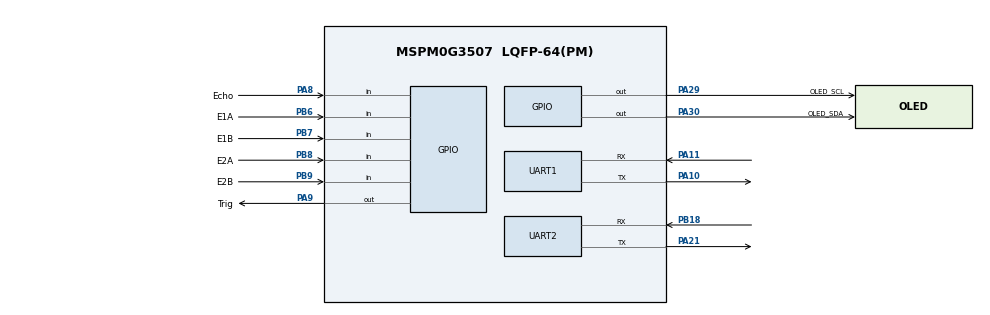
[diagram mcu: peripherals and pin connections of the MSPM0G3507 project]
/**
 * These arguments were used when this file was generated. They will be automatically applied on subsequent loads
 * via the GUI or CLI. Run CLI with '--help' for additional information on how to override these arguments.
 * @cliArgs --device "MSPM0G350X" --part "Default" --package "LQFP-64(PM)" --product "mspm0_sdk@2.10.00.04"
 * @v2CliArgs --device "MSPM0G3507" --package "LQFP-64(PM)" --product "mspm0_sdk@2.10.00.04"
 * @versions {"tool":"1.27.0+4565"}
 */

/**
 * Import the modules used in this configuration.
 */
const GPIO   = scripting.addModule("/ti/driverlib/GPIO", {}, false);
const GPIO1  = GPIO.addInstance();
const GPIO2  = GPIO.addInstance();
const GPIO3  = GPIO.addInstance();
const SYSCTL = scripting.addModule("/ti/driverlib/SYSCTL");
const TIMER  = scripting.addModule("/ti/driverlib/TIMER", {}, false);
const TIMER1 = TIMER.addInstance();
const TIMER2 = TIMER.addInstance();
const UART   = scripting.addModule("/ti/driverlib/UART", {}, false);
const UART1  = UART.addInstance();
const UART2  = UART.addInstance();

/**
 * Write custom configuration values to the imported modules.
 */
GPIO1.port                                = "PORTB";
GPIO1.$name                               = "ENCODER";
GPIO1.associatedPins.create(4);
GPIO1.associatedPins[0].$name             = "E1A";
GPIO1.associatedPins[0].direction         = "INPUT";
GPIO1.associatedPins[0].interruptEn       = true;
GPIO1.associatedPins[0].polarity          = "RISE";
GPIO1.associatedPins[0].assignedPin       = "6";
GPIO1.associatedPins[0].internalResistor  = "PULL_DOWN";
GPIO1.associatedPins[0].interruptPriority = "0";
GPIO1.associatedPins[0].pin.$assign       = "PB6";
GPIO1.associatedPins[1].$name             = "E1B";
GPIO1.associatedPins[1].direction         = "INPUT";
GPIO1.associatedPins[1].assignedPin       = "7";
GPIO1.associatedPins[1].interruptEn       = true;
GPIO1.associatedPins[1].polarity          = "RISE";
GPIO1.associatedPins[1].internalResistor  = "PULL_DOWN";
GPIO1.associatedPins[1].interruptPriority = "0";
GPIO1.associatedPins[1].pin.$assign       = "PB7";
GPIO1.associatedPins[2].$name             = "E2A";
GPIO1.associatedPins[2].direction         = "INPUT";
GPIO1.associatedPins[2].interruptEn       = true;
GPIO1.associatedPins[2].polarity          = "RISE";
GPIO1.associatedPins[2].assignedPin       = "8";
GPIO1.associatedPins[2].internalResistor  = "PULL_DOWN";
GPIO1.associatedPins[2].interruptPriority = "0";
GPIO1.associatedPins[2].pin.$assign       = "PB8";
GPIO1.associatedPins[3].$name             = "E2B";
GPIO1.associatedPins[3].direction         = "INPUT";
GPIO1.associatedPins[3].interruptEn       = true;
GPIO1.associatedPins[3].polarity          = "RISE";
GPIO1.associatedPins[3].assignedPin       = "9";
GPIO1.associatedPins[3].internalResistor  = "PULL_DOWN";
GPIO1.associatedPins[3].interruptPriority = "0";
GPIO1.associatedPins[3].pin.$assign       = "PB9";

const Board = scripting.addModule("/ti/driverlib/Board", {}, false);

GPIO2.port                                = "PORTA";
GPIO2.$name                               = "SR04";
GPIO2.associatedPins.create(2);
GPIO2.associatedPins[0].assignedPin       = "9";
GPIO2.associatedPins[0].$name             = "Trig";
GPIO2.associatedPins[0].initialValue      = "SET";
GPIO2.associatedPins[0].pin.$assign       = "PA9";
GPIO2.associatedPins[1].direction         = "INPUT";
GPIO2.associatedPins[1].assignedPin       = "8";
GPIO2.associatedPins[1].interruptEn       = true;
GPIO2.associatedPins[1].polarity          = "RISE_FALL";
GPIO2.associatedPins[1].$name             = "Echo";
GPIO2.associatedPins[1].interruptPriority = "1";
GPIO2.associatedPins[1].pin.$assign       = "PA8";

GPIO3.$name                         = "OLED";
GPIO3.port                          = "PORTA";
GPIO3.associatedPins.create(2);
GPIO3.associatedPins[0].$name       = "OLED_SCL";
GPIO3.associatedPins[0].assignedPin = "29";
GPIO3.associatedPins[0].pin.$assign = "PA29";
GPIO3.associatedPins[1].$name       = "OLED_SDA";
GPIO3.associatedPins[1].assignedPin = "30";
GPIO3.associatedPins[1].pin.$assign = "PA30";

SYSCTL.forceDefaultClkConfig = true;

TIMER1.timerMode          = "PERIODIC";
TIMER1.interrupts         = ["ZERO"];
TIMER1.timerStartTimer    = true;
TIMER1.$name              = "TIMER_ENCODER";
TIMER1.timerClkDiv        = 8;
TIMER1.timerClkPrescale   = 10;
TIMER1.interruptPriority  = "0";
TIMER1.timerPeriod        = "10 ms";
TIMER1.peripheral.$assign = "TIMA0";

TIMER2.timerPeriod        = "1 ms";
TIMER2.timerStartTimer    = true;
TIMER2.timerMode          = "PERIODIC_UP";
TIMER2.interrupts         = ["LOAD"];
TIMER2.$name              = "TIMER_SR04";
TIMER2.timerClkPrescale   = 40;
TIMER2.interruptPriority  = "1";
TIMER2.peripheral.$assign = "TIMA1";

UART1.$name                    = "UART_0";
UART1.peripheral.$assign       = "UART0";
UART1.peripheral.rxPin.$assign = "PA11";
UART1.peripheral.txPin.$assign = "PA10";
UART1.txPinConfig.$name        = "ti_driverlib_gpio_GPIOPinGeneric0";
UART1.rxPinConfig.$name        = "ti_driverlib_gpio_GPIOPinGeneric1";

UART2.$name                            = "Bluetooth";
UART2.targetBaudRate                   = 115200;
UART2.enabledInterrupts                = ["RX"];
UART2.interruptPriority                = "0";
UART2.peripheral.$assign               = "UART2";
UART2.peripheral.rxPin.$assign         = "PB18";
UART2.peripheral.txPin.$assign         = "PA21";
UART2.txPinConfig.$name                = "ti_driverlib_gpio_GPIOPinGeneric2";
UART2.txPinConfig.direction            = scripting.forceWrite("OUTPUT");
UART2.txPinConfig.hideOutputInversion  = scripting.forceWrite(false);
UART2.txPinConfig.onlyInternalResistor = scripting.forceWrite(false);
UART2.txPinConfig.passedPeripheralType = scripting.forceWrite("Digital");
UART2.rxPinConfig.$name                = "ti_driverlib_gpio_GPIOPinGeneric3";
UART2.rxPinConfig.hideOutputInversion  = scripting.forceWrite(false);
UART2.rxPinConfig.onlyInternalResistor = scripting.forceWrite(false);
UART2.rxPinConfig.passedPeripheralType = scripting.forceWrite("Digital");

/**
 * Pinmux solution for unlocked pins/peripherals. This ensures that minor changes to the automatic solver in a future
 * version of the tool will not impact the pinmux you originally saw.  These lines can be completely deleted in order to
 * re-solve from scratch.
 */
Board.peripheral.$suggestSolution          = "DEBUGSS";
Board.peripheral.swclkPin.$suggestSolution = "PA20";
Board.peripheral.swdioPin.$suggestSolution = "PA19";
SYSCTL.peripheral.$suggestSolution         = "SYSCTL";
